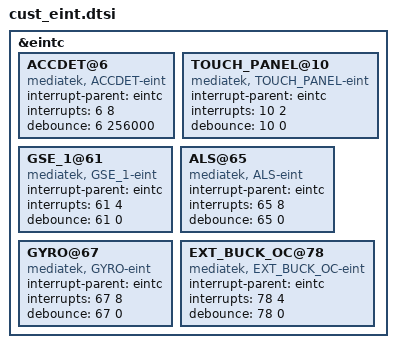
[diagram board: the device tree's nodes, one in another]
/*
 * Generated by MTK SP DrvGen Version 03.13.6 for MT6735M. Copyright MediaTek Inc. (C) 2013.
 * Sun May 08 00:05:28 2016
 * Do Not Modify the File.
 */

/*************************
 * EINT DTSI File
*************************/

&eintc {
	ACCDET@6 {
		compatible = "mediatek, ACCDET-eint";
		interrupt-parent = <&eintc>;
		interrupts = <6 8>;
		debounce = <6 256000>;
	};

	TOUCH_PANEL@10 {
		compatible = "mediatek, TOUCH_PANEL-eint";
		interrupt-parent = <&eintc>;
		interrupts = <10 2>;
		debounce = <10 0>;
	};

	GSE_1@61 {
		compatible = "mediatek, GSE_1-eint";
		interrupt-parent = <&eintc>;
		interrupts = <61 4>;
		debounce = <61 0>;
	};

	ALS@65 {
		compatible = "mediatek, ALS-eint";
		interrupt-parent = <&eintc>;
		interrupts = <65 8>;
		debounce = <65 0>;
	};

	GYRO@67 {
		compatible = "mediatek, GYRO-eint";
		interrupt-parent = <&eintc>;
		interrupts = <67 8>;
		debounce = <67 0>;
	};

	EXT_BUCK_OC@78 {
		compatible = "mediatek, EXT_BUCK_OC-eint";
		interrupt-parent = <&eintc>;
		interrupts = <78 4>;
		debounce = <78 0>;
	};

};
